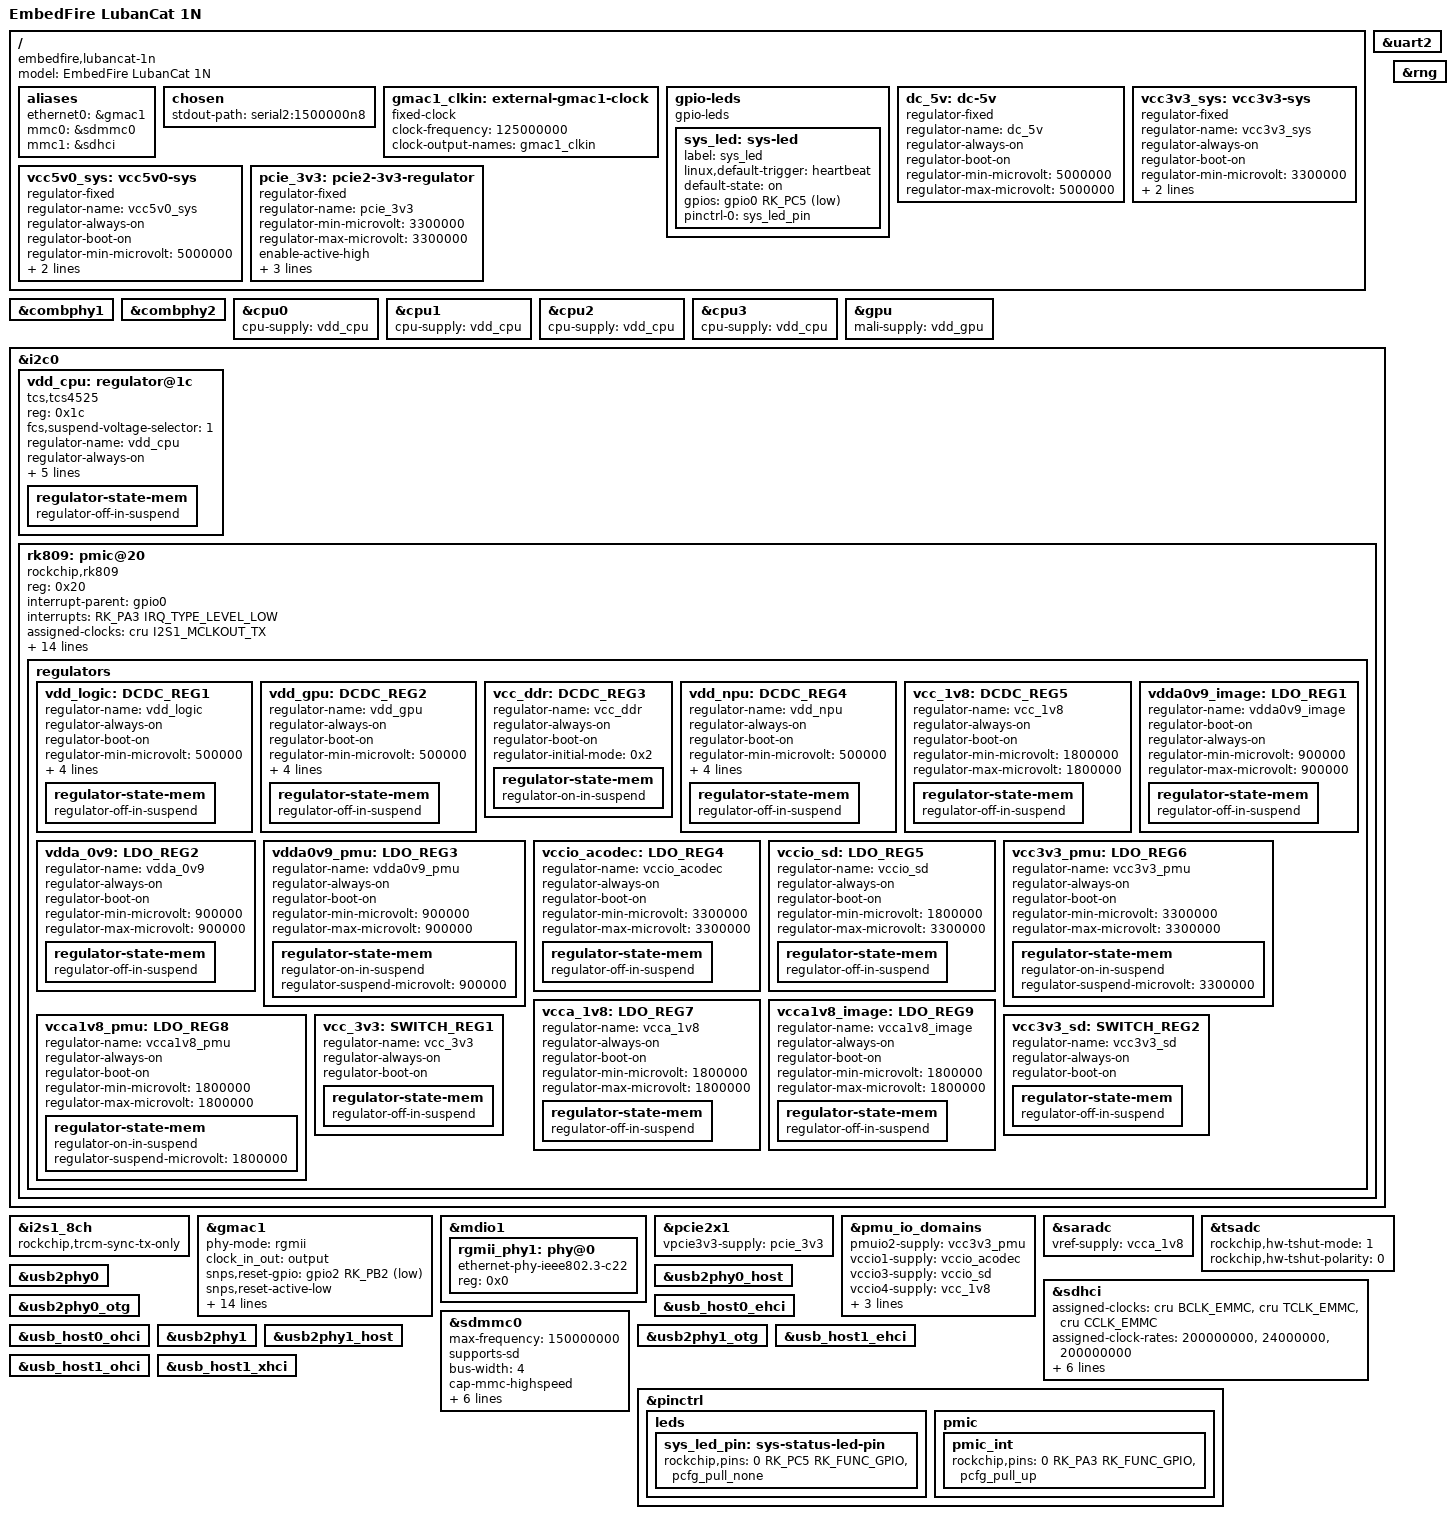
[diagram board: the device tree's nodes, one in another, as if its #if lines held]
// SPDX-License-Identifier: (GPL-2.0+ OR MIT)
/*
* Copyright (c) 2021 Rockchip Electronics Co., Ltd.
* Copyright (c) 2022 EmbedFire <embedfire@embedfire.com>
*/

/dts-v1/;
#include <dt-bindings/gpio/gpio.h>
#include <dt-bindings/leds/common.h>
#include <dt-bindings/pinctrl/rockchip.h>
#include <dt-bindings/soc/rockchip,vop2.h>
#include "rk3566.dtsi"

/ {
	model = "EmbedFire LubanCat 1N";
	compatible = "embedfire,lubancat-1n", "rockchip,rk3566";

	aliases {
		ethernet0 = &gmac1;
		mmc0 = &sdmmc0;
		mmc1 = &sdhci;
	};

	chosen: chosen {
		stdout-path = "serial2:1500000n8";
	};

	gmac1_clkin: external-gmac1-clock {
		compatible = "fixed-clock";
		clock-frequency = <125000000>;
		clock-output-names = "gmac1_clkin";
		#clock-cells = <0>;
	};
	
	gpio-leds {
		compatible = "gpio-leds";

		sys_led: sys-led {
			label = "sys_led";
			linux,default-trigger = "heartbeat";
			default-state = "on";
			gpios = <&gpio0 RK_PC5 GPIO_ACTIVE_LOW>;
			pinctrl-names = "default";
			pinctrl-0 = <&sys_led_pin>;
		};
	};

	dc_5v: dc-5v {
		compatible = "regulator-fixed";
		regulator-name = "dc_5v";
		regulator-always-on;
		regulator-boot-on;
		regulator-min-microvolt = <5000000>;
		regulator-max-microvolt = <5000000>;
	};

	vcc3v3_sys: vcc3v3-sys {
		compatible = "regulator-fixed";
		regulator-name = "vcc3v3_sys";
		regulator-always-on;
		regulator-boot-on;
		regulator-min-microvolt = <3300000>;
		regulator-max-microvolt = <3300000>;
		vin-supply = <&vcc5v0_sys>;
	};

	vcc5v0_sys: vcc5v0-sys {
		compatible = "regulator-fixed";
		regulator-name = "vcc5v0_sys";
		regulator-always-on;
		regulator-boot-on;
		regulator-min-microvolt = <5000000>;
		regulator-max-microvolt = <5000000>;
		vin-supply = <&dc_5v>;
	};

	pcie_3v3: pcie2-3v3-regulator {
		compatible = "regulator-fixed";
		regulator-name = "pcie_3v3";
		regulator-min-microvolt = <3300000>;
		regulator-max-microvolt = <3300000>;
		enable-active-high;
		gpio = <&gpio3 RK_PC3 GPIO_ACTIVE_HIGH>;
		startup-delay-us = <5000>;
		vin-supply = <&vcc5v0_sys>;
	};
};

&uart2 {
	status = "okay";
};

&combphy1 {
	status = "okay";
};

&combphy2 {
	status = "okay";
};

&cpu0 {
	cpu-supply = <&vdd_cpu>;
};

&cpu1 {
	cpu-supply = <&vdd_cpu>;
};

&cpu2 {
	cpu-supply = <&vdd_cpu>;
};

&cpu3 {
	cpu-supply = <&vdd_cpu>;
};

#ifdef DTS_NO_LEGACY
&gpu {
	mali-supply = <&vdd_gpu>;
	status = "okay";
};
#endif

&i2c0 {
	status = "okay";

	vdd_cpu: regulator@1c {
		compatible = "tcs,tcs4525";
		reg = <0x1c>;
		fcs,suspend-voltage-selector = <1>;
		regulator-name = "vdd_cpu";
		regulator-always-on;
		regulator-boot-on;
		regulator-min-microvolt = <800000>;
		regulator-max-microvolt = <1150000>;
		regulator-ramp-delay = <2300>;
		vin-supply = <&vcc5v0_sys>;

		regulator-state-mem {
			regulator-off-in-suspend;
		};
	};

	rk809: pmic@20 {
		compatible = "rockchip,rk809";
		reg = <0x20>;
		interrupt-parent = <&gpio0>;
		interrupts = <RK_PA3 IRQ_TYPE_LEVEL_LOW>;
		assigned-clocks = <&cru I2S1_MCLKOUT_TX>;
		assigned-clock-parents = <&cru CLK_I2S1_8CH_TX>;
		#clock-cells = <1>;
		clock-names = "mclk";
		clocks = <&cru I2S1_MCLKOUT_TX>;
		pinctrl-names = "default";
		pinctrl-0 = <&pmic_int>;
		rockchip,system-power-controller;
		#sound-dai-cells = <0>;
		vcc1-supply = <&vcc3v3_sys>;
		vcc2-supply = <&vcc3v3_sys>;
		vcc3-supply = <&vcc3v3_sys>;
		vcc4-supply = <&vcc3v3_sys>;
		vcc5-supply = <&vcc3v3_sys>;
		vcc6-supply = <&vcc3v3_sys>;
		vcc7-supply = <&vcc3v3_sys>;
		vcc8-supply = <&vcc3v3_sys>;
		vcc9-supply = <&vcc3v3_sys>;
		wakeup-source;

		regulators {
			vdd_logic: DCDC_REG1 {
				regulator-name = "vdd_logic";
				regulator-always-on;
				regulator-boot-on;
				regulator-min-microvolt = <500000>;
				regulator-max-microvolt = <1350000>;
				regulator-init-microvolt = <900000>;
				regulator-ramp-delay = <6001>;
				regulator-initial-mode = <0x2>;

				regulator-state-mem {
					regulator-off-in-suspend;
				};
			};

			vdd_gpu: DCDC_REG2 {
				regulator-name = "vdd_gpu";
				regulator-always-on;
				regulator-boot-on;
				regulator-min-microvolt = <500000>;
				regulator-max-microvolt = <1350000>;
				regulator-init-microvolt = <900000>;
				regulator-ramp-delay = <6001>;
				regulator-initial-mode = <0x2>;

				regulator-state-mem {
					regulator-off-in-suspend;
				};
			};

			vcc_ddr: DCDC_REG3 {
				regulator-name = "vcc_ddr";
				regulator-always-on;
				regulator-boot-on;
				regulator-initial-mode = <0x2>;

				regulator-state-mem {
					regulator-on-in-suspend;
				};
			};

			vdd_npu: DCDC_REG4 {
				regulator-name = "vdd_npu";
				regulator-always-on;
				regulator-boot-on;
				regulator-min-microvolt = <500000>;
				regulator-max-microvolt = <1350000>;
				regulator-init-microvolt = <900000>;
				regulator-ramp-delay = <6001>;
				regulator-initial-mode = <0x2>;

				regulator-state-mem {
					regulator-off-in-suspend;
				};
			};

			vcc_1v8: DCDC_REG5 {
				regulator-name = "vcc_1v8";
				regulator-always-on;
				regulator-boot-on;
				regulator-min-microvolt = <1800000>;
				regulator-max-microvolt = <1800000>;

				regulator-state-mem {
					regulator-off-in-suspend;
				};
			};

			vdda0v9_image: LDO_REG1 {
				regulator-name = "vdda0v9_image";
				regulator-boot-on;
				regulator-always-on;
				regulator-min-microvolt = <900000>;
				regulator-max-microvolt = <900000>;

				regulator-state-mem {
					regulator-off-in-suspend;
				};
			};

			vdda_0v9: LDO_REG2 {
				regulator-name = "vdda_0v9";
				regulator-always-on;
				regulator-boot-on;
				regulator-min-microvolt = <900000>;
				regulator-max-microvolt = <900000>;

				regulator-state-mem {
					regulator-off-in-suspend;
				};
			};

			vdda0v9_pmu: LDO_REG3 {
				regulator-name = "vdda0v9_pmu";
				regulator-always-on;
				regulator-boot-on;
				regulator-min-microvolt = <900000>;
				regulator-max-microvolt = <900000>;

				regulator-state-mem {
					regulator-on-in-suspend;
					regulator-suspend-microvolt = <900000>;
				};
			};

			vccio_acodec: LDO_REG4 {
				regulator-name = "vccio_acodec";
				regulator-always-on;
				regulator-boot-on;
				regulator-min-microvolt = <3300000>;
				regulator-max-microvolt = <3300000>;

				regulator-state-mem {
					regulator-off-in-suspend;
				};
			};

			vccio_sd: LDO_REG5 {
				regulator-name = "vccio_sd";
				regulator-always-on;
				regulator-boot-on;
				regulator-min-microvolt = <1800000>;
				regulator-max-microvolt = <3300000>;

				regulator-state-mem {
					regulator-off-in-suspend;
				};
			};

			vcc3v3_pmu: LDO_REG6 {
				regulator-name = "vcc3v3_pmu";
				regulator-always-on;
				regulator-boot-on;
				regulator-min-microvolt = <3300000>;
				regulator-max-microvolt = <3300000>;

				regulator-state-mem {
					regulator-on-in-suspend;
					regulator-suspend-microvolt = <3300000>;
				};
			};

			vcca_1v8: LDO_REG7 {
				regulator-name = "vcca_1v8";
				regulator-always-on;
				regulator-boot-on;
				regulator-min-microvolt = <1800000>;
				regulator-max-microvolt = <1800000>;

				regulator-state-mem {
					regulator-off-in-suspend;
				};
			};

			vcca1v8_pmu: LDO_REG8 {
				regulator-name = "vcca1v8_pmu";
				regulator-always-on;
				regulator-boot-on;
				regulator-min-microvolt = <1800000>;
				regulator-max-microvolt = <1800000>;

				regulator-state-mem {
					regulator-on-in-suspend;
					regulator-suspend-microvolt = <1800000>;
				};
			};

			vcca1v8_image: LDO_REG9 {
				regulator-name = "vcca1v8_image";
				regulator-always-on;
				regulator-boot-on;
				regulator-min-microvolt = <1800000>;
				regulator-max-microvolt = <1800000>;

				regulator-state-mem {
					regulator-off-in-suspend;
				};
			};

			vcc_3v3: SWITCH_REG1 {
				regulator-name = "vcc_3v3";
				regulator-always-on;
				regulator-boot-on;

				regulator-state-mem {
					regulator-off-in-suspend;
				};
			};

			vcc3v3_sd: SWITCH_REG2 {
				regulator-name = "vcc3v3_sd";
				regulator-always-on;
				regulator-boot-on;

				regulator-state-mem {
					regulator-off-in-suspend;
				};
			};
		};
	};
};

#ifdef DTS_NO_LEGACY
&i2s1_8ch {
	rockchip,trcm-sync-tx-only;
	status = "okay";
};
#endif

&gmac1 {
    phy-mode = "rgmii";
    clock_in_out = "output";

    snps,reset-gpio = <&gpio2 RK_PB2 GPIO_ACTIVE_LOW>;
    snps,reset-active-low;
    /* Reset time is 100ms, 100ms */
    snps,reset-delays-us = <0 75000 100000>;

    assigned-clocks = <&cru SCLK_GMAC1_RX_TX>, <&cru SCLK_GMAC1>;
    assigned-clock-parents = <&cru SCLK_GMAC1_RGMII_SPEED>, <&cru CLK_MAC1_2TOP>;
    assigned-clock-rates = <0>, <125000000>;

    pinctrl-names = "default";
    pinctrl-0 = <&gmac1m1_miim
             &gmac1m1_tx_bus2_level3
             &gmac1m1_rx_bus2
             &gmac1m1_rgmii_clk_level2
             &gmac1m1_rgmii_bus_level3>;

    tx_delay = <0x24>;
    rx_delay = <0x08>;

    phy-handle = <&rgmii_phy1>;
    status = "okay";
};

&mdio1 {
    rgmii_phy1: phy@0 {
        compatible = "ethernet-phy-ieee802.3-c22";
        reg = <0x0>;
    };
};

&pcie2x1 {
	vpcie3v3-supply = <&pcie_3v3>;
	status = "okay";
};

&pmu_io_domains {
	pmuio2-supply = <&vcc3v3_pmu>;
	vccio1-supply = <&vccio_acodec>;
	vccio3-supply = <&vccio_sd>;
	vccio4-supply = <&vcc_1v8>;
	vccio5-supply = <&vcc_3v3>;
	vccio6-supply = <&vcc_1v8>;
	vccio7-supply = <&vcc_3v3>;
	status = "okay";
};

&rng {
	status = "okay";
};

&saradc {
	vref-supply = <&vcca_1v8>;
	status = "okay";
};

&tsadc {
	rockchip,hw-tshut-mode = <1>;
	rockchip,hw-tshut-polarity = <0>;
	status = "okay";
};

&sdhci {
	assigned-clocks = <&cru BCLK_EMMC>, <&cru TCLK_EMMC>, <&cru CCLK_EMMC>;
	assigned-clock-rates = <200000000>, <24000000>, <200000000>;
	bus-width = <8>;
	max-frequency = <200000000>;
	mmc-hs200-1_8v;		
	non-removable;	
	pinctrl-names = "default";
	pinctrl-0 = <&emmc_bus8 &emmc_clk &emmc_cmd>;	
	supports-emmc;
	status = "okay";
};

&sdmmc0 {
    max-frequency = <150000000>;
    supports-sd;
    bus-width = <4>;
    cap-mmc-highspeed;
    cap-sd-highspeed;
    disable-wp;
    vmmc-supply = <&vcc3v3_sd>;
    vqmmc-supply = <&vccio_sd>;
    pinctrl-names = "default";
    pinctrl-0 = <&sdmmc0_bus4 &sdmmc0_clk &sdmmc0_cmd &sdmmc0_det>;
    status = "okay";
};

/* USB OTG/USB Host_1 USB 2.0 Comb */
&usb2phy0 {
	status = "okay";
};

&usb2phy0_host {
	status = "okay";
};

&usb2phy0_otg {
	status = "okay";
};

&usb_host0_ehci {
	status = "okay";
};

&usb_host0_ohci {
	status = "okay";
};

/* USB Host_2/USB Host_3 USB 2.0 Comb */
&usb2phy1 {
	status = "okay";
};

&usb2phy1_host {
	status = "okay";
};

&usb2phy1_otg {
	status = "okay";
};

&usb_host1_ehci {
	status = "okay";
};

&usb_host1_ohci {
	status = "okay";
};

/* USB3.0 Host */
&usb_host1_xhci {
	status = "okay";
};

&pinctrl {
	leds {
		sys_led_pin: sys-status-led-pin {
			rockchip,pins = <0 RK_PC5 RK_FUNC_GPIO &pcfg_pull_none>;
		};
	};

	pmic {
		pmic_int: pmic_int {
			rockchip,pins =
				<0 RK_PA3 RK_FUNC_GPIO &pcfg_pull_up>;
		};
	};
};
